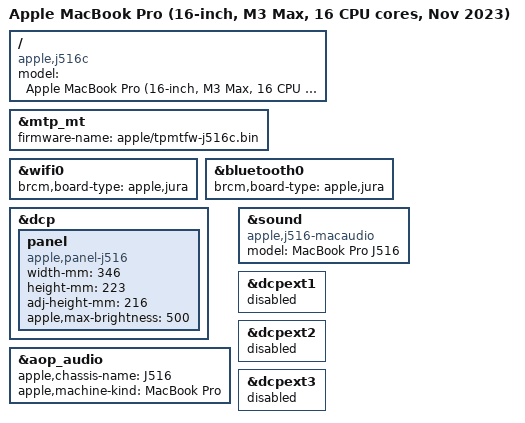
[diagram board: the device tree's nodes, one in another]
// SPDX-License-Identifier: GPL-2.0+ OR MIT
/*
 * MacBook Pro (16-inch, M3 Max, 16 CPU cores, Nov 2023)
 *
 * target-type: J516c
 *
 * Copyright The Asahi Linux Contributors
 */

/dts-v1/;

#include "t6031.dtsi"
#include "t6031-dcp.dtsi"
#include "t603x-j514-j516.dtsi"
#include "t603x-j514c-j516c-dcpext.dtsi"
#include "t603x-j514c-j516c-hdmi.dtsi"

/ {
	compatible = "apple,j516c", "apple,t6031", "apple,arm-platform";
	model = "Apple MacBook Pro (16-inch, M3 Max, 16 CPU cores, Nov 2023)";
};

&mtp_mt {
	firmware-name = "apple/tpmtfw-j516c.bin";
};

&wifi0 {
	brcm,board-type = "apple,jura";
};

&bluetooth0 {
	brcm,board-type = "apple,jura";
};

/*
 * The J516S values (t6030-j516s.dts): the same chassis and panel.
 * Not yet read from a J516C.
 */
&dcp {
	panel {
		compatible = "apple,panel-j516", "apple,panel-mini-led", "apple,panel";
		width-mm = <346>;
		height-mm = <223>;
		adj-height-mm = <216>;
		apple,max-brightness = <500>;
	};
};

&aop_audio {
	apple,chassis-name = "J516";
	apple,machine-kind = "MacBook Pro";
};

&sound {
	compatible = "apple,j516-macaudio", "apple,j316-macaudio", "apple,macaudio";
	model = "MacBook Pro J516";
};

/*
 * On this J516C only dcpext0 brings up an external display: dcpext1..3 time
 * out in the DPTX remote port (HPD assert, link configuration) on USB-C and
 * on the HDMI route alike. Keep them away from the display gate, which only
 * enables processors left "disabled", so the allocator always picks dcpext0.
 * The DRM device waits only for available processors.
 */
&dcpext1 {
	status = "fail";
};

&dcpext2 {
	status = "fail";
};

&dcpext3 {
	status = "fail";
};
